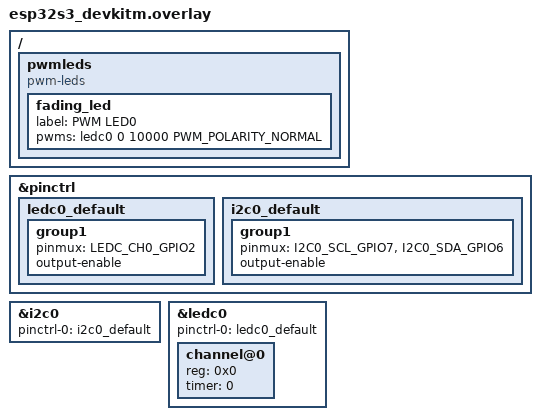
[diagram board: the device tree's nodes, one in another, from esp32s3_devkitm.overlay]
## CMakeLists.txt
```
cmake_minimum_required(VERSION 3.20)
set(BOARD esp32s3_devkitm)

find_package(Zephyr)
project(i2c)

FILE(GLOB app_sources src/*.c)
target_sources(app PRIVATE ${app_sources})
target_include_directories(app PRIVATE include)
```

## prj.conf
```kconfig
CONFIG_PWM=y
# Adding I2C
CONFIG_I2C=y
```

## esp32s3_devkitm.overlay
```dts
#include <dt-bindings/pwm/pwm.h>

/ {
	pwmleds {
		compatible = "pwm-leds";
		fading_led: fading_led {
		   label = "PWM LED0";
		   pwms = <&ledc0 0 10000 PWM_POLARITY_NORMAL>;
		};
	};
};

&pinctrl {
	ledc0_default: ledc0_default {
		group1 {
			pinmux = <LEDC_CH0_GPIO2>;
			output-enable;
		};
	};

	i2c0_default: i2c0_default {
		group1 {
			pinmux = <I2C0_SCL_GPIO7>, <I2C0_SDA_GPIO6>;
			output-enable;
		};
	};
};

&i2c0 {
	status = "okay";
	pinctrl-0 = <&i2c0_default>;
	pinctrl-names = "default";
};

&ledc0 {
	pinctrl-0 = <&ledc0_default>;
	pinctrl-names = "default";
	status = "okay";
	#address-cells = <1>;
	#size-cells = <0>;
	channel@0{
		reg = <0x0>;
		timer = <0>;
	};
};
```

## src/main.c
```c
#include <zephyr/kernel.h>
#include <zephyr/device.h>
#include <zephyr/drivers/pwm.h>
#include <zephyr/drivers/gpio.h>
#include <zephyr/drivers/i2c.h>

#include <stdio.h>

#include "pwmled.h"

#define MPU6050_AD0 5


#define MPU6050_REG_CHIP_ID		0x75
#define MPU6050_CHIP_ID			0x68
#define MPU9250_CHIP_ID			0x71

#define MPU6050_REG_GYRO_CFG		0x1B
#define MPU6050_GYRO_FS_SHIFT		3

#define MPU6050_REG_ACCEL_CFG		0x1C
#define MPU6050_ACCEL_FS_SHIFT		3

#define MPU6050_REG_INT_EN		0x38
#define MPU6050_DRDY_EN			BIT(0)

#define MPU6050_REG_DATA_START		0x3B

#define MPU6050_REG_PWR_MGMT1		0x6B
#define MPU6050_SLEEP_EN		BIT(6)

static const struct device *gpio_dev0 = 
  DEVICE_DT_GET(DT_NODELABEL(gpio0));


K_TIMER_DEFINE(led_delta_timer, led_delta_timer_handler, NULL);

void main(void)
{
	if(!device_is_ready(fading_led.dev))
	{
		printk("Error: PWM device not ready\n");
		while(true);
	}
  if(!device_is_ready(gpio_dev0))
  {
    printk("Error: GPIO not ready\n");
    while(true);
  }

  pulse_width_delta_nsec = fading_led.period / NUM_STEPS;

  int ret;
  ret = gpio_pin_configure(gpio_dev0, MPU6050_AD0, GPIO_OUTPUT_INACTIVE);

	k_timer_start(&led_delta_timer, 
					K_MSEC(SLEEP_DELTA_MSEC), 
					K_MSEC(SLEEP_DELTA_MSEC));

  //MPU6050 settings
  uint8_t chipId = 0;
  const struct device *i2c_dev0 = DEVICE_DT_GET(DT_NODELABEL(i2c0));
  int nack;
  uint8_t value;   

  nack = i2c_reg_read_byte(i2c_dev0,MPU6050_CHIP_ID,MPU6050_REG_CHIP_ID, &value);
  if(!nack)
  {
    printf("I2C WAMI Value %x\n", value);
  }
  else
  {
    printf("Error Read: I2C\n");
    while(true);
  }
  nack = i2c_reg_update_byte(i2c_dev0, MPU6050_CHIP_ID, MPU6050_REG_PWR_MGMT1, MPU6050_SLEEP_EN, 0);

  while (true)
  {
		k_msleep(1000);


    int16_t buf[7];
    nack = i2c_burst_read(i2c_dev0, MPU6050_CHIP_ID, MPU6050_REG_DATA_START, (uint8_t *)buf, 14);

    if(!nack)
    {
      for(int i = 0; i < 7; i++)
      {
        printf("SensorReading[%d] = %x\n", i, buf[i]);
      }
    }
    else
    {
      printf("Sensor Reading Error\n:");
    }
    
		printf("Hello World! %s\n", CONFIG_BOARD);
  }
  
}
```

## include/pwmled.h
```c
#define NUM_STEPS 100U
#define SLEEP_DELTA_MSEC 5U

extern const struct pwm_dt_spec fading_led ;

extern uint32_t pulse_width_nsec;
extern uint32_t pulse_width_delta_nsec;
extern uint32_t steps_taken;
extern bool increasing_intensity;

void led_delta_timer_handler(struct k_timer *timer_info);
```

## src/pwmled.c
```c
#include <zephyr/kernel.h>
#include <zephyr/device.h>
#include <zephyr/drivers/pwm.h>

#include "pwmled.h"

const struct pwm_dt_spec fading_led =
  PWM_DT_SPEC_GET(DT_NODELABEL(fading_led));

uint32_t pulse_width_nsec = 0U;
uint32_t pulse_width_delta_nsec = 0U;
uint32_t steps_taken = 0U;
bool increasing_intensity = true;

void led_delta_timer_handler(struct k_timer *timer_info)
{
    int ret;
    if (increasing_intensity) {
    if (steps_taken < NUM_STEPS) {
      ret = pwm_set_pulse_dt(&fading_led, pulse_width_nsec);
      steps_taken++;
      pulse_width_nsec += pulse_width_delta_nsec;
    } else {
      increasing_intensity = false;
      steps_taken--;
      pulse_width_nsec -= pulse_width_delta_nsec;
    }
  } else {
    if (steps_taken > 0) {
      ret = pwm_set_pulse_dt(&fading_led, pulse_width_nsec);
      steps_taken--;
      pulse_width_nsec -= pulse_width_delta_nsec;
    } else {
      increasing_intensity = true;
      steps_taken++;
      pulse_width_nsec += pulse_width_delta_nsec;
    }
  }
}
```
